VERSION "HIPBNYYYYYYYYYYYYYYYYYYYYYYYYYYYYYYYYYYYYY/4/%%%/4/'%**4YYY///"

NS_ :

BS_:

BU_: ElconCharger BMS

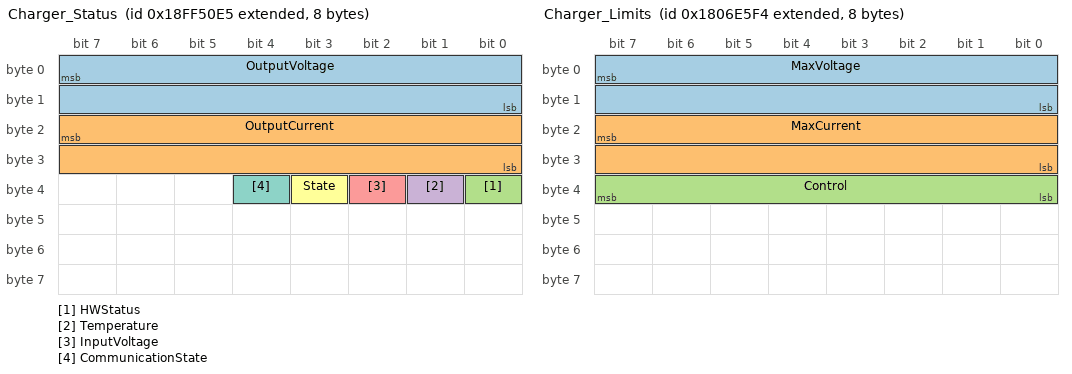
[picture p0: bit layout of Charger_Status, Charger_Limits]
BO_ 2566869221 Charger_Status: 8 ElconCharger
 SG_ OutputVoltage : 7|16@0+ (0.1,0) [0|0] "V" Vector__XXX
 SG_ OutputCurrent : 23|16@0+ (0.1,0) [0|0] "A" Vector__XXX
 SG_ HWStatus : 32|1@1+ (1,0) [0|0] "" Vector__XXX
 SG_ Temperature : 33|1@1+ (1,0) [0|0] "" Vector__XXX
 SG_ InputVoltage : 34|1@1+ (1,0) [0|0] "" Vector__XXX
 SG_ State : 35|1@1+ (1,0) [0|0] "" Vector__XXX
 SG_ CommunicationState : 36|1@1+ (1,0) [0|0] "" Vector__XXX

BO_ 2550588916 Charger_Limits: 8 BMS
 SG_ MaxVoltage : 7|16@0+ (0.1,0) [0|0] "V" Vector__XXX
 SG_ MaxCurrent : 23|16@0+ (0.1,0) [0|0] "A" Vector__XXX
 SG_ Control : 32|8@1+ (1,0) [0|0] "" Vector__XXX

CM_ SG_ 2566869221 OutputVoltage "Output Voltage";
CM_ SG_ 2566869221 OutputCurrent "Output Current";
CM_ SG_ 2566869221 HWStatus "Charger status";
CM_ SG_ 2566869221 Temperature "Charger temperature";
CM_ SG_ 2566869221 InputVoltage "Charger input voltage";
CM_ SG_ 2566869221 State "Charger starting state";
CM_ SG_ 2566869221 CommunicationState "Charger communication state";
CM_ SG_ 2550588916 MaxVoltage "Max Allowable Charging Terminal Voltage";
CM_ SG_ 2550588916 MaxCurrent "Max Allowable Charging Current";
CM_ SG_ 2550588916 Control "Toggle charging";

BA_DEF_ BO_  "GenMsgCycleTime" INT 2 50000;
BA_DEF_DEF_  "GenMsgCycleTime" 100;
BA_ "GenMsgCycleTime" BO_ 2566869221 1000;
BA_ "GenMsgCycleTime" BO_ 2550588916 1000;

VAL_ 2566869221 HWStatus 0 "HW_STATUS_OK" 1 "HW_STATUS_FAIL" ;
VAL_ 2566869221 Temperature 0 "TEMP_OK" 1 "TEMP_FAULT" ;
VAL_ 2566869221 InputVoltage 0 "INPUT_VOLTAGE_OK" 1 "INPUT_VOLTAGE_FAULT" ;
VAL_ 2566869221 State 0 "STATE_CHARGING" 1 "STATE_OFF" ;
VAL_ 2566869221 CommunicationState 0 "COMM_STATE_OK" 1 "COMM_STATE_TIMEOUT" ;
VAL_ 2550588916 Control 1 "CHARGING_STOP" 0 "CHARGING_START" ;
